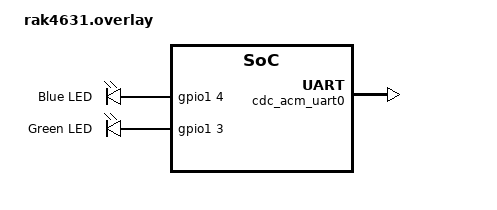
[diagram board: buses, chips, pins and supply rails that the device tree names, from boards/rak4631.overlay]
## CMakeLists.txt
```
# SPDX-License-Identifier: Apache-2.0

cmake_minimum_required(VERSION 3.20.0)

find_package(Zephyr REQUIRED HINTS $ENV{ZEPHYR_BASE})
project(sleep_test)

target_sources(app PRIVATE src/main.c)

target_sources_ifdef(CONFIG_BT_PERIPHERAL app PRIVATE src/rak_ble_peripheral.c)
if(CONFIG_USE_SEGGER_RTT AND CONFIG_BOARD_RAK11720)
  target_sources(app PRIVATE src/rtt.c)
endif()
```

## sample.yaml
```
sample:
  name: LoRa Sleep Test
tests:
  sample.lora.sleep_test.rak3112:
    platform_allow:
      - rak3112/esp32s3/procpu
    sysbuild: true
    tags: rak
    build_only: true
  sample.lora.sleep_test.rak3172:
    platform_allow:
      - rak3172
      - rak11160
    extra_args: EXTRA_CONF_FILE=overlay_sleep_rak3172.conf
    tags: rak
    build_only: true
  sample.lora.sleep_test.rak4631:
    platform_allow:
      - rak4631
    extra_args: EXTRA_CONF_FILE=overlay_ble.conf;overlay_sleep_rak4631.conf
    tags: rak
    build_only: true
  sample.lora.sleep_test.rak11720:
    platform_allow:
      - rak11720
    extra_args: EXTRA_CONF_FILE=overlay_ble.conf;overlay_sleep_rak11720.conf
    tags: rak
    build_only: true
```

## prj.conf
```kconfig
CONFIG_GPIO=y
CONFIG_SPI=y
CONFIG_SPI_LOG_LEVEL_DBG=y
CONFIG_LORA=y
CONFIG_LORA_LOG_LEVEL_DBG=y

CONFIG_MAIN_STACK_SIZE=2048
CONFIG_SYSTEM_WORKQUEUE_STACK_SIZE=2048

CONFIG_LOG=y
CONFIG_LOG_PRINTK=n
# Open following lines to
# use RTT logging for debug!!!
# CONFIG_USE_SEGGER_RTT=y
# CONFIG_LOG_BACKEND_RTT=y
# CONFIG_LOG_BACKEND_UART=n
```

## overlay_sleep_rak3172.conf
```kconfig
# Necessary options for low power consumption
CONFIG_PINCTRL=y
CONFIG_PM=y
CONFIG_PM_DEVICE=y
CONFIG_PM_DEVICE_RUNTIME=y
CONFIG_PM_DEVICE_SYSTEM_MANAGED=y

# Disable hardware features not in use
CONFIG_I2C=n
CONFIG_ADC=n
CONFIG_PWM=n

# With lpuart, it is possible to enabled it
# without increasing idle current.
# Please close logging at your production code!!!
# CONFIG_LOG=n
# CONFIG_LOG_PRINTK=n
# CONFIG_LOG_BACKEND_RTT=n
# CONFIG_CONSOLE=n
# CONFIG_UART_CONSOLE=n
# CONFIG_SERIAL=n
CONFIG_BOOT_BANNER=n
CONFIG_DEBUG=n
CONFIG_DEBUG_THREAD_INFO=n
CONFIG_DEBUG_OPTIMIZATIONS=n
CONFIG_RTT_CONSOLE=n
CONFIG_USB_DEVICE_STACK=n
CONFIG_STDOUT_CONSOLE=n
CONFIG_CBPRINTF_FP_SUPPORT=n
```

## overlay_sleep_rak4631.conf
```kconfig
# Necessary options for low power consumption
CONFIG_PM_DEVICE=y
CONFIG_LOG=n
CONFIG_LOG_PRINTK=n
CONFIG_BOOT_BANNER=n
CONFIG_DEBUG=n
CONFIG_DEBUG_THREAD_INFO=n
CONFIG_DEBUG_OPTIMIZATIONS=n
# Open to disable USB stack if you need!!!
# RAK4631 uses USB stack and it does not cause to
# increase on idle current.
# CONFIG_SERIAL=n
# CONFIG_UART_INTERRUPT_DRIVEN=n
# CONFIG_CONSOLE=n
# CONFIG_UART_CONSOLE=n
# CONFIG_RTT_CONSOLE=n
# CONFIG_USB_DEVICE_STACK=n
```

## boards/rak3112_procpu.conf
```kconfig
CONFIG_LOG_MODE_IMMEDIATE=y

CONFIG_POWEROFF=y
```

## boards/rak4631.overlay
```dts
/ {
	aliases {
		blue-led = &blue_led;
		green-led = &green_led;
	};

	leds {
		compatible = "gpio-leds";
		blue_led: led_2 {
			gpios = <&gpio1 4 GPIO_ACTIVE_HIGH>;
			label = "Blue LED";
		};
		green_led: led_1 {
			gpios = <&gpio1 3 GPIO_ACTIVE_HIGH>;
			label = "Green LED";
		};
	};
};

/ {
	chosen {
		zephyr,console = &cdc_acm_uart0;
	};
};

&uart0 {
	status = "disabled";
};

&uart1 {
	status = "disabled";
};

&zephyr_udc0 {
	cdc_acm_uart0: cdc_acm_uart0 {
		compatible = "zephyr,cdc-acm-uart";
	};
};
```

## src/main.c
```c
#include <stdio.h>
#include <zephyr/kernel.h>
#include <zephyr/drivers/gpio.h>
#include <zephyr/drivers/lora.h>
#include <zephyr/drivers/regulator.h>
#include <zephyr/irq.h>

#if defined(CONFIG_BOARD_RAK3112)
#include <esp_sleep.h>
#include <driver/rtc_io.h>
#endif

#include "rak_ble_peripheral.h"

#include <zephyr/logging/log.h>
LOG_MODULE_REGISTER(main, LOG_LEVEL_DBG);

/*
 * Get LED GPIO
 */
static const struct gpio_dt_spec led = GPIO_DT_SPEC_GET(DT_ALIAS(green_led), gpios);

static void led_init()
{
	if (!gpio_is_ready_dt(&led)) {
		LOG_ERR("LED is not ready!");
		return;
	}

	int ret = gpio_pin_configure_dt(&led, GPIO_OUTPUT_ACTIVE);
	if (ret) {
		LOG_ERR("Failed to configure LED!");
	}

	ret = gpio_pin_set_dt(&led, 1); // ON
	if (ret) {
		LOG_ERR("Failed to control LED!");
	}
	k_msleep(1000);
	ret = gpio_pin_set_dt(&led, 0); // OFF
	if (ret) {
		LOG_ERR("Failed to control LED!");
	}

	ret = gpio_pin_configure_dt(&led, GPIO_DISCONNECTED);
	if (ret) {
		LOG_ERR("Failed to disconnect LED!");
	}
}

#if defined(CONFIG_BOARD_RAK11160)
/*
 * Get ESP8684 enable regulator
 */
static const struct device *esp = DEVICE_DT_GET(DT_NODELABEL(esp8684_enable));
#endif

/*
 * Get LoRa device
 */
static const struct device *lora_dev = DEVICE_DT_GET(DT_ALIAS(lora0));

int main(void)
{
#if defined(CONFIG_BT_PERIPHERAL)
	int ret = rak_ble_peripheral_init();
	if (ret) {
		LOG_ERR("Failed to init ble peripheral: %d", ret);
		return -1;
	}
#endif

#if defined(CONFIG_BOARD_RAK11160)
	// Suspend ESP MCU
	int ret = regulator_disable(esp);
	if (ret) {
		LOG_ERR("Failed to suspend esp: %d", ret);
	}
#endif

	if (!device_is_ready(lora_dev)) {
		LOG_ERR("%s: device not ready.", lora_dev->name);
		return -1;
	}

	led_init();

	LOG_INF("Sleep Test! %s", CONFIG_BOARD);

#if defined(CONFIG_BOARD_RAK3112)
	switch (esp_sleep_get_wakeup_cause()) {
	case ESP_SLEEP_WAKEUP_TIMER:
		LOG_INF("Wake up from timer.");
		break;
	case ESP_SLEEP_WAKEUP_UNDEFINED:
	default:
		LOG_INF("Not a deep sleep reset.");
	}

	/* Enabling timer wakeup for 30 seconds */
	esp_sleep_enable_timer_wakeup(30 * 1000000);

	/* Hold related pins on required levels during deep sleep */
	uint8_t dio1_pin = 47;
	uint8_t reset_pin = 8;
	uint8_t cs_pin = 7;
	rtc_gpio_pulldown_en((gpio_num_t)dio1_pin);
	rtc_gpio_pullup_en((gpio_num_t)reset_pin);
	rtc_gpio_pullup_en((gpio_num_t)cs_pin);

	LOG_INF("Powering off...");

	k_busy_wait(1000000);

	(void)irq_lock();

	/* For timer wakeup you must leave RTC peripherals ON */
	esp_sleep_pd_config(ESP_PD_DOMAIN_RTC_PERIPH, ESP_PD_OPTION_ON);
	esp_deep_sleep_start();

	/* Never reached here! */
#endif

	while (1) {
		k_sleep(K_FOREVER);
	}

	return 0;
}
```

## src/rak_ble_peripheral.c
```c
#include <stdio.h>

#include <zephyr/kernel.h>
#include <zephyr/device.h>

#include <zephyr/bluetooth/bluetooth.h>
#include <zephyr/bluetooth/hci.h>
#include <zephyr/bluetooth/conn.h>
#include <zephyr/bluetooth/gatt.h>

#include "rak_ble_peripheral.h"

#include <zephyr/logging/log.h>
LOG_MODULE_REGISTER(ble_peripheral, LOG_LEVEL_INF);

#define DEVICE_NAME     CONFIG_BT_DEVICE_NAME
#define DEVICE_NAME_LEN (sizeof(DEVICE_NAME) - 1)

/* Advertising data */
static const struct bt_data ad[] = {
	BT_DATA_BYTES(BT_DATA_FLAGS, BT_LE_AD_NO_BREDR),
	BT_DATA_BYTES(BT_DATA_SVC_DATA16, 0xaa, 0xfe, /* Eddystone UUID */
		      0x10,                           /* Eddystone-URL frame type */
		      0x00,                           /* Calibrated Tx power at 0m */
		      0x01,                           /* URL Scheme Prefix https://www. */
		      'r', 'a', 'k', 'w', 'i', 'r', 'e', 'l', 'e', 's', 's', 0x07 /* .com */
		      )};

/* Scan response data */
static const struct bt_data sd[] = {BT_DATA(BT_DATA_NAME_COMPLETE, DEVICE_NAME, DEVICE_NAME_LEN)};

static void adv_stop_work_handler(struct k_work *work)
{
	LOG_INF("Advertising stopped");
	bt_le_adv_stop();
}
static K_WORK_DELAYABLE_DEFINE(adv_stop_work, adv_stop_work_handler);

static void adv_start_work_handler(struct k_work *work)
{
	bt_le_adv_stop();

	int err = bt_le_adv_start(BT_LE_ADV_NCONN_IDENTITY, ad, ARRAY_SIZE(ad), sd, ARRAY_SIZE(sd));
	if (err) {
		LOG_ERR("Advertising failed to start (err %d)", err);
		return;
	}

	LOG_INF("Advertising successfully started");
	k_work_reschedule(&adv_stop_work, K_SECONDS(30));
}
K_WORK_DEFINE(adv_start_work, adv_start_work_handler);

static void bt_ready_handler(int err)
{
	if (err) {
		LOG_ERR("Ble peripheral init failed (err %d)", err);
		return;
	}

	k_work_submit(&adv_start_work);
}

int rak_ble_peripheral_init(void)
{
	int err = bt_enable(bt_ready_handler);
	if (err) {
		LOG_ERR("Bluetooth init failed (err %d)", err);
		return err;
	}

	return err;
}
```
